# LPC18xx register map
File version: 18
Registers are 32-bit, read-write, reset 0x0 unless marked. A register's access mark holds for its fields unless they carry their own. Offsets are from the block's base; [hi:lo] are bit positions; {n}, {i} and the like mark numbered series.

## ADC0 — Product name title=UM10430 Chapter title=LPC18xx 10-bit ADC0/1 Modification date=1/18/2011 Major revision=0 Minor revision=7
Base 0x400E3000
Same registers: ADC1 0x400E4000
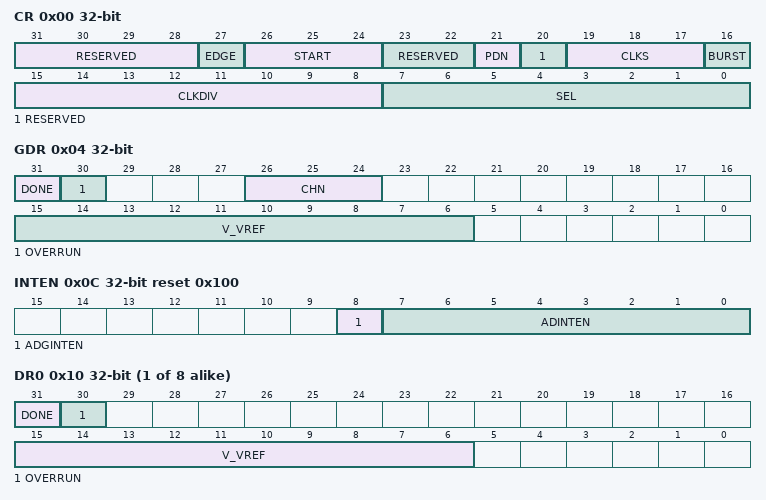
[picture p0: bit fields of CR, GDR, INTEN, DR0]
0x00 CR — A/D Control Register. The AD0CR register must be written to select the operating mode before A/D conversion can occur.
  [31:28] RESERVED — Reserved, user software should not write ones to reserved bits. The value read from a reserved bit is not defined.
  [27] EDGE — This bit is significant only when the START field contains 0x2 -0x6. In these cases:
    0=RISING (Start conversion on a rising edge on the selected signal.); 1=FALLING (Start conversion on a falling edge on the selected signal.)
  [26:24] START — When the BURST bit is 0, these bits control whether and when an A/D conversion is started (also see Figure 56):
    0=NO_START_(THIS_VALUE (No start (this value should be used when clearing PDN to 0).); 1=START_CONVERSION_NOW; 2=CTOUT_15 (Start conversion when the edge selected by bit 27 occurs on CTOUT_15 (combined timer output 15).); 3=CTOUT_8 (Start conversion when the edge selected by bit 27 occurs on CTOUT_8 (combined timer output 8).); 4=ADCTRIG0 (Start conversion when the edge selected by bit 27 occurs on ADCTRIG0 input.); 5=ADCTRIG1 (Start conversion when the edge selected by bit 27 occurs on ADCTRIG1 input.); 6=MCOA2 (Start conversion when the edge selected by bit 27 occurs on Motocon PWM output MCOA2.)
  [23:22] RESERVED — Reserved, user software should not write ones to reserved bits. The value read from a reserved bit is not defined.
  [21] PDN — Power mode
    0=POWERDOWN (The A/D converter is in Power-down mode.); 1=RUNNING (The A/D converter is operational.)
  [20] RESERVED — Reserved, user software should not write ones to reserved bits. The value read from a reserved bit is not defined.
  [19:17] CLKS — This field selects the number of clocks used for each conversion in Burst mode, and the number of bits of accuracy of the result in the LS bits of ADDR, between 11 clocks (10 bits) and 4 clocks (3 bits).
    0=11_CLOCKS_/_10_BITS; 1=10_CLOCKS_/_9_BITS; 2=9_CLOCKS_/_8_BITS; 3=8_CLOCKS_/_7_BITS; 4=7_CLOCKS_/_6_BITS; 5=6_CLOCKS_/_5_BITS; 6=5_CLOCKS_/_4_BITS; 7=4_CLOCKS_/_3_BITS
  [16] BURST — Burst mode
    0=SOFTWARE (Conversions are software controlled and require 11 clocks.); 1=BURST (The AD converter does repeated conversions at the rate selected by the CLKS field, scanning (if necessary) through the pins selected by 1s in the SEL field. The first conversion after the start corresponds to the least-significant 1 in the SEL field, then higher numbered 1 bits (pins) if applicable. Repeated conversions can be terminated by clearing this bit, but the conversion that is in progress when this bit is cleared will be completed. Important: START bits must be 000 when BURST = 1 or conversions will not start.)
  [15:8] CLKDIV — The ADC clock is divided by the CLKDIV value plus one to produce the clock for the A/D converter, which should be less than or equal to 4.5 MHz. Typically, software should program the smallest value in this field that yields a clock of 4.5 MHz or slightly less, but in certain cases (such as a high-impedance analog source) a slower clock may be desirable.
  [7:0] SEL — Selects which of the ADC[7:0] pins are to be sampled and converted. Bit 0 selects Pin ADC0, bit 1 selects pin AD1,..., and bit 7 selects pin ADC7. In software-controlled mode, only one of these bits should be 1. In hardware scan mode, any value containing 1 to 8 ones. All zeroes is equivalent to 0x01.
0x04 GDR ro reset not defined — A/D Global Data Register. Contains the result of the most recent A/D conversion.
  [31] DONE — This bit is set to 1 when an analog-to-digital conversion completes. It is cleared when this register is read and when the AD0/1CR register is written. If the AD0/1CR is written while a conversion is still in progress, this bit is set and a new conversion is started.
  [30] OVERRUN — This bit is 1 in burst mode if the results of one or more conversions was (were) lost and overwritten before the conversion that produced the result in the V_VREF bits.
  [26:24] CHN — These bits contain the channel from which the LS bits were converted.
  [15:6] V_VREF — When DONE is 1, this field contains a binary fraction representing the voltage on the ADCn pin selected by the SEL field, divided by the reference voltage on the VDDA pin. Zero in the field indicates that the voltage on the ADCn input pin was less than, equal to, or close to that on VSSA, while 0x3FF indicates that the voltage on ADCn input pin was close to, equal to, or greater than that on VDDA.
0x0C INTEN reset 0x100 — A/D Interrupt Enable Register. This register contains enable bits that allow the DONE flag of each A/D channel to be included or excluded from contributing to the generation of an A/D interrupt.
  [8] ADGINTEN — When 1, enables the global DONE flag in ADDR to generate an interrupt. When 0, only the individual A/D channels enabled by ADINTEN 7:0 will generate interrupts.
  [7:0] ADINTEN — These bits allow control over which A/D channels generate interrupts for conversion completion. When bit 0 is one, completion of a conversion on A/D channel 0 will generate an interrupt, when bit 1 is one, completion of a conversion on A/D channel 1 will generate an interrupt, etc.
{0x10+4i} DR{i} (i=0..7) ro — A/D Channel Data Register. This register contains the result of the most recent conversion completed on channel n.
  [31] DONE — This bit is set to 1 when an A/D conversion completes. It is cleared when this register is read.
  [30] OVERRUN — This bit is 1 in burst mode if the results of one or more conversions was (were) lost and overwritten before the conversion that produced the result in the V_VREF bits in this register.This bit is cleared by reading this register.
  [15:6] V_VREF — When DONE is 1, this field contains a binary fraction representing the voltage on the ADCn input pin selected in Table 727, divided by the voltage on the VDDA pin. Zero in the field indicates that the voltage on the ADCn input pin was less than, equal to, or close to that on VDDA, while 0x3FF indicates that the voltage on ADCn input pin was close to, equal to, or greater than that on VDDA.
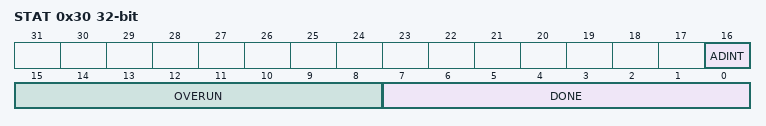
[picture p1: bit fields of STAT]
0x30 STAT ro — A/D Status Register. This register contains DONE and OVERRUN flags for all of the A/D channels, as well as the A/D interrupt flag.
  [16] ADINT — This bit is the A/D interrupt flag. It is one when any of the individual A/D channel Done flags is asserted and enabled to contribute to the A/D interrupt via the ADINTEN register.
  [15:8] OVERUN — These bits mirror the OVERRRUN status flags that appear in the result register for each A/D channel. Reading ADSTAT allows checking the status of all A/D channels simultaneously.
  [7:0] DONE — These bits mirror the DONE status flags that appear in the result register for each A/D channel.
